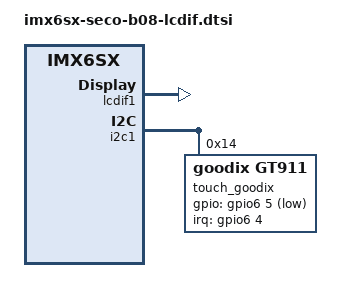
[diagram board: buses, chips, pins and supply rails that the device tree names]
/*
 * Copyright (C) 2016 Seco s.r.l.
 * Author: Giuseppe Pagano <giuseppe.pagano@seco.com>
 *
 * This program is free software; you can redistribute it and/or modify
 * it under the terms of the GNU General Public License version 2 as
 * published by the Free Software Foundation.
 */

&lcdif1 {
        pinctrl-names = "default";
        pinctrl-0 = <&pinctrl_lcdif_dat_0
        &pinctrl_lcdif_ctrl_0>;
        lcd-supply = <&vgen5_reg>;
        display = <&display0>;
        status = "okay";

        display0: display {
                bits-per-pixel = <32>;
                bus-width = <24>;

                display-timings {
                        native-mode = <&timing0>;
                        timing0: timing0 {
                                clock-frequency = <38000000>;
                                hactive = <800>;
                                vactive = <480>;
                                hback-porch = <56>;
                                hfront-porch = <50>;
                                vback-porch = <20>;
                                vfront-porch = <53>;
                                hsync-len = <180>;
                                vsync-len = <30>;

                                hsync-active = <0>;
                                vsync-active = <1>;
                                de-active = <1>;
                                pixelclk-active = <0>;
                        };
                };
        };
};

&i2c1 {
        touch_goodix: gt911@14 {
                compatible = "goodix,gt911";
                reg = <0x14>;
 		pinctrl-names = "default";
 		pinctrl-0 = <&pinctrl_gt911>;
                interrupt-parent = <&gpio6>;
 		interrupts = <4 IRQ_TYPE_LEVEL_LOW>;
		gpios = <&gpio6 5 GPIO_ACTIVE_LOW>;
 		interrupt-gpio = <164>;
 		reset-gpio = <165>;
		ts-max-width = <800>;
		ts-max-height = <480>;
		ts-max-finger = <1>;
        };
};

